# LPC15xx register map
File version: 0.7
LPC15xx Cortex-M3 MCU; up to 64 kB flash; up to 12 kB SRAM; USB device; USART; EEPROM
CPU: CM3 r2p1, little endian, no MPU, no FPU, 3 interrupt priority bits
Registers are 32-bit, read-write, reset 0x0 unless marked. A register's access mark holds for its fields unless they carry their own. Offsets are from the block's base; lines under a group give offsets from that group; [hi:lo] are bit positions; {n}, {i} and the like mark numbered series; 'fields as' and 'values as' point back to an identical list; <NAME> marks a mode.

## Memory map
0x1C000000 GPIO_PORT size 0x40000 — General Purpose I/O (GPIO)
0x1C004000 DMA size 0x1000 — DMA controller
0x1C00C000 USB size 0x1000 — USB device controller
0x1C010000 CRC size 0x1000 — Cyclic Redundancy Check (CRC) engine
0x1C018000 SCT0 size 0x1000 — Large State Configurable Timers 0/1 (SCT0/1)
0x1C01C000 SCT1 size 0x1000
0x1C020000 SCT2 size 0x1000 — Small State Configurable Timers 2/3 (SCT2/3)
0x1C024000 SCT3 size 0x1000
0x40000000 ADC0 size 0x1000 — 12-bit ADC controller ADC0/1
0x40004000 DAC size 0x1000 — 12-bit DAC Modification
0x40008000 ACMP size 0x1000 — Analog comparators ACMP0/1/2/3
0x40014000 INMUX size 0x1000 — Input multiplexing (INMUX)
0x40028000 RTC size 0x1000 — Real-Time Clock (RTC)
0x4002C000 WWDT size 0x1000 — Windowed Watchdog Timer (WWDT)
0x40038000 SWM size 0x1000 — Switch Matrix (SWM)
0x4003C000 PMU size 0x1000 — Power Management Unit (PMU)
0x40040000 USART0 size 0x1000
0x40044000 USART1 size 0x1000
0x40048000 SPI0 size 0x1000
0x4004C000 SPI1 size 0x1000
0x40050000 I2C0 size 0x1000 — I2C-bus interface
0x40058000 QEI size 0x1000 — Quadrature Encoder Interface (QEI)
0x40074000 SYSCON size 0x1000 — System configuration (SYSCON)
0x40080000 ADC1 size 0x1000
0x400A0000 MRT size 0x1000 — Multi-Rate Timer (MRT)
0x400A4000 PINT size 0x1000 — Pin interrupt and pattern match (PINT)
0x400A8000 GINT0 size 0x1000 — Group interrupt 0/1 (GINT0/1)
0x400AC000 GINT1 size 0x1000
0x400B4000 RIT size 0x1000 — Repetitive Interrupt Timer (RIT)
0x400B8000 SCTIPU size 0x1000 — SCT Input Processing Unit (IPU)
0x400BC000 FLASHCTRL size 0x1000 — Flash controller
0x400C0000 USART2 size 0x1000
0x400F0000 C_CAN0 size 0x1000 — Controller Area Network C_CAN0
0x400F8000 IOCON size 0x1000 — I/O pin configuration (IOCON)

## Interrupts
0 WDT (WWDT)
1 BOD_IRQ (SYSCON)
2 FLASH (FLASHCTRL)
3 EE (FLASHCTRL)
4 DMA
5 GINT0
6 GINT1
{n+7} PIN_INT{n} (PINT) (n=0..7)
15 RIT
16 SCT0
17 SCT1
18 SCT2
19 SCT3
20 MRT
21 UART0 (USART0)
22 UART1 (USART1)
23 UART2 (USART2)
24 I2C0
25 SPI0
26 SPI1
27 C_CAN0
28 USB_IRQ (USB)
29 USB_FIQ (USB)
30 USBWAKEUP (USB)
31 ADC0_SEQA (ADC0)
32 ADC0_SEQB (ADC0)
33 ADC0_THCMP (ADC0)
34 ADC0_OVR (ADC0)
35 ADC1_SEQA (ADC1)
36 ADC1_SEQB (ADC1)
37 ADC1_THCMP (ADC1)
38 ADC1_OVR (ADC1)
39 DAC
40 CMP0 (ACMP)
41 CMP1 (ACMP)
42 CMP2 (ACMP)
43 CMP3 (ACMP)
44 QEI
45 RTC_ALARM (RTC)
46 RTC_WAKE (RTC)

## GPIO_PORT — General Purpose I/O (GPIO)
Base 0x1C000000
{0x0+i} B[{i}] (i=0..75) 8-bit reset not defined — Byte pin registers
  [0] PBYTE — Read: state of the pin PIOm_n, regardless of direction, masking, or alternate function, except that pins configured as analog I/O always read as 0. One register for each port pin: m = port 0 to 2; n = pin 0 to 31 for port 0 and 1 and pin 0 to 11 for port 2. Write: loads the pin's output bit.
{0x1000+4i} W[{i}] (i=0..75) reset not defined — Word pin registers
  [31:0] PWORD — Read 0: pin PIOm_n is LOW. Write 0: clear output bit. Read 0xFFFF FFFF: pin PIOm_n is HIGH. Write any value 0x0000 0001 to 0xFFFF FFFF: set output bit. Only 0 or 0xFFFF FFFF can be read. Writing any value other than 0 will set the output bit. One register for each port pin: m = port 0 to 2; n = pin 0 to 31 for port 0 and 1 and pin 0 to 11 for port2.
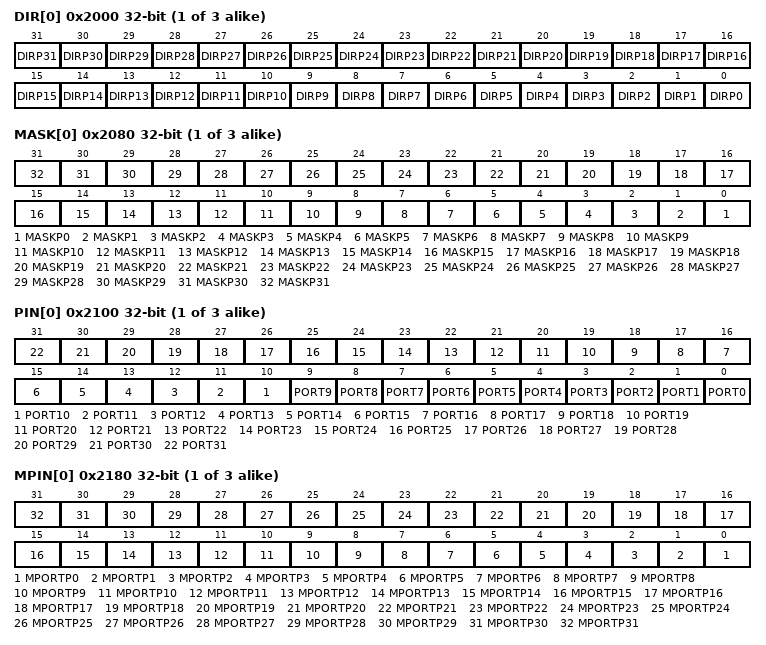
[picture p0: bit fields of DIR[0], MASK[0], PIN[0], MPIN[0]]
{0x2000+4i} DIR[{i}] (i=0..2) — Port Direction registers
  [n] DIRP{n} (n=0..31) — Selects pin direction for pin PIOm_n (bit 0 = PIOm_0, bit 1 = PIOm_1, ..., bit 31 = PIOm_31). m = port 0 to 2; n = pin 0 to 31 for port 0 and 1 and pin 0 to 11 for port2. 0 = input. 1 = output.
{0x2080+4i} MASK[{i}] (i=0..2) — Port Mask register
  [n] MASKP{n} (n=0..31) — Controls which bits corresponding to PIOm_n are active in the MPORT register (bit 0 = PIOm_0, bit 1 = PIOm_1, ..., bit 31 = PIOm_31). m = port 0 to 2; n = pin 0 to 31 for port 0 and 1 and pin 0 to 11 for port2. 0 = Read MPORT: pin state; write MPORT: load output bit. 1 = Read MPORT: 0; write MPORT: output bit not affected.
{0x2100+4i} PIN[{i}] (i=0..2) reset not defined — Port pin register
  [n] PORT{n} (n=0..31) — Reads pin states or loads output bits (bit 0 = PIOm_0, bit 1 = PIOm_1, ..., bit 31 = PIOm_31). m = port 0 to 2; n = pin 0 to 31 for port 0 and 1 and pin 0 to 11 for port2. 0 = Read: pin is low; write: clear output bit. 1 = Read: pin is high; write: set output bit.
{0x2180+4i} MPIN[{i}] (i=0..2) reset not defined — Masked port register
  [n] MPORTP{n} (n=0..31) — Masked port register (bit 0 = PIOm_0, bit 1 =PIOm_1, ..., bit 31 = PIOm_31). m = port 0 to 2; n = pin 0 to 31 for port 0 and 1 and pin 0 to 11 for port2. 0 = Read: pin is LOW and/or the corresponding bit in the MASK register is 1; write: clear output bit if the corresponding bit in the MASK register is 0. 1 = Read: pin is HIGH and the corresponding bit in the MASK register is 0; write: set output bit if the corresponding bit in the MASK register is 0.
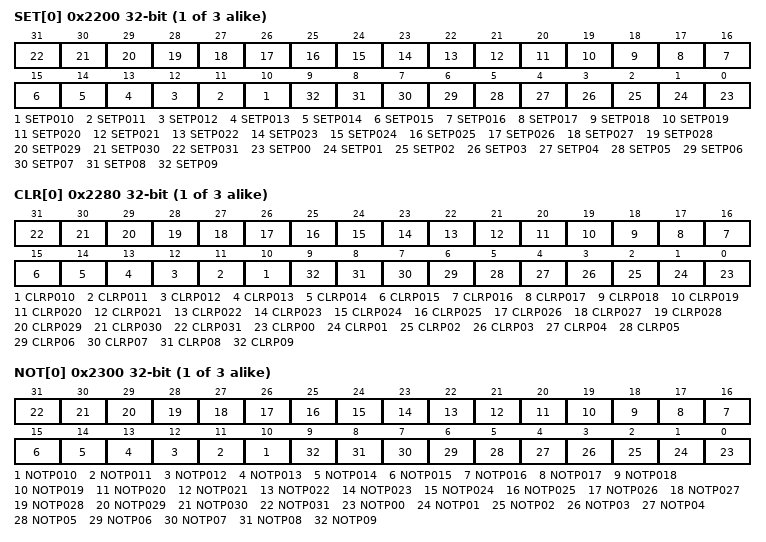
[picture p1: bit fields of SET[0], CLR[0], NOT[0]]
{0x2200+4i} SET[{i}] (i=0..2) — Write: Set port register Read: port output bits
  [n] SETP{n:03} (n=10..31) — Read or set output bits. 0 = Read: output bit: write: no operation. 1 = Read: output bit; write: set output bit.
  [n] SETP{n:02} (n=0..9) — Read or set output bits. 0 = Read: output bit: write: no operation. 1 = Read: output bit; write: set output bit.
{0x2280+4i} CLR[{i}] (i=0..2) wo reset not defined — Clear port
  [n] CLRP{n:03} (n=10..31) — Clear output bits: 0 = No operation. 1 = Clear output bit.
  [n] CLRP{n:02} (n=0..9) — Clear output bits: 0 = No operation. 1 = Clear output bit.
{0x2300+4i} NOT[{i}] (i=0..2) wo reset not defined — Toggle port
  [n] NOTP{n:03} (n=10..31) — Toggle output bits: 0 = no operation. 1 = Toggle output bit.
  [n] NOTP{n:02} (n=0..9) — Toggle output bits: 0 = no operation. 1 = Toggle output bit.
